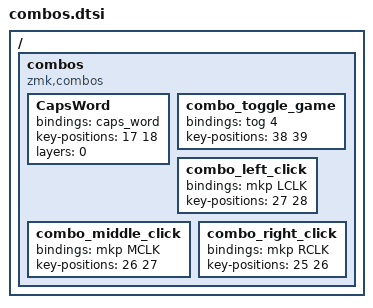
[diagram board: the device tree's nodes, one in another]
/ {
    combos {
        compatible = "zmk,combos";

        CapsWord {
            bindings = <&caps_word>;
            key-positions = <17 18>;
            layers = <0>;
        };

        combo_toggle_game {
            bindings = <&tog 4>;
            key-positions = <38 39>;
        };
        
        combo_left_click {
            bindings = <&mkp LCLK>;
            key-positions = <27 28>;
        };

        combo_middle_click {
            bindings = <&mkp MCLK>;
            key-positions = <26 27>;
        };

        combo_right_click {
            bindings = <&mkp RCLK>;
            key-positions = <25 26>;
        };
    };
};
